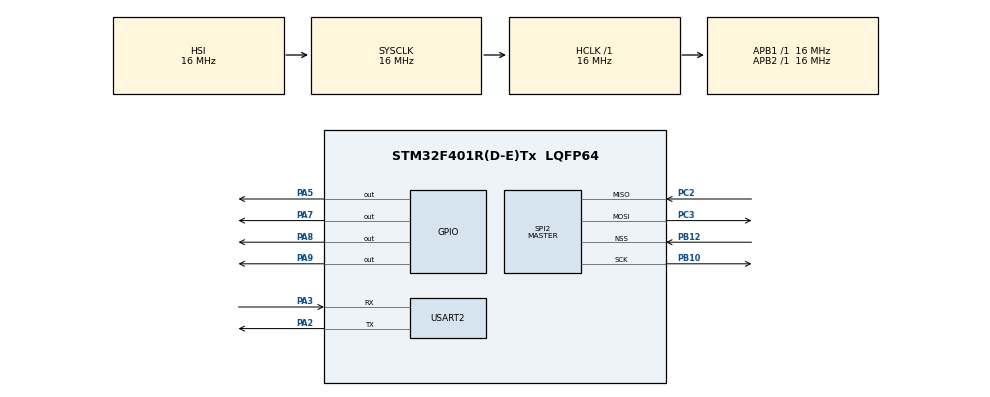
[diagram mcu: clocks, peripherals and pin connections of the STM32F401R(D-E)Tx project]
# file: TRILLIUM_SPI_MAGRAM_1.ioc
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Mcu.Family=STM32F4
Mcu.Name=STM32F401R(D-E)Tx
Mcu.Package=LQFP64
NVIC.PriorityGroup=NVIC_PRIORITYGROUP_4
PA2.Mode=Asynchronous
PA2.Signal=USART2_TX
PA3.Mode=Asynchronous
PA3.Signal=USART2_RX
PA5.Signal=GPIO_Output
PA7.Signal=GPIO_Output
PA8.Signal=GPIO_Output
PA9.Signal=GPIO_Output
PB10.Mode=Full_Duplex_Master
PB10.Signal=SPI2_SCK
PB12.Mode=NSS_Signal_Hard_Input
PB12.Signal=SPI2_NSS
PC2.Mode=Full_Duplex_Master
PC2.Signal=SPI2_MISO
PC3.Mode=Full_Duplex_Master
PC3.Signal=SPI2_MOSI
ProjectManager.HeapSize=0x200
ProjectManager.StackSize=0x400
ProjectManager.TargetToolchain=SW4STM32
RCC.AHBFreq_Value=16000000
RCC.APB1Freq_Value=16000000
RCC.APB2Freq_Value=16000000
RCC.CortexFreq_Value=16000000
RCC.HSE_VALUE=25000000
RCC.HSI_VALUE=16000000
RCC.LSE_VALUE=32768
RCC.SYSCLKFreq_VALUE=16000000
RCC.VCOOutputFreq_Value=192000000
SPI2.Direction=SPI_DIRECTION_2LINES
SPI2.Mode=SPI_MODE_MASTER
SPI2.VirtualNSS=VM_NSSHARD
SPI2.VirtualType=VM_MASTER
USART2.VirtualMode=VM_ASYNC
board=custom

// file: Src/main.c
/**
  ******************************************************************************
  * @file           : main.c
  * @brief          : Main program body
  ******************************************************************************
  ** This notice applies to any and all portions of this file
  * that are not between comment pairs USER CODE BEGIN and
  * USER CODE END. Other portions of this file, whether
  * inserted by the user or by software development tools
  * are owned by their respective copyright owners.
  *
  * COPYRIGHT(c) 2019 STMicroelectronics
  *
  * Redistribution and use in source and binary forms, with or without modification,
  * are permitted provided that the following conditions are met:
  *   1. Redistributions of source code must retain the above copyright notice,
  *      this list of conditions and the following disclaimer.
  *   2. Redistributions in binary form must reproduce the above copyright notice,
  *      this list of conditions and the following disclaimer in the documentation
  *      and/or other materials provided with the distribution.
  *   3. Neither the name of STMicroelectronics nor the names of its contributors
  *      may be used to endorse or promote products derived from this software
  *      without specific prior written permission.
  *
  * THIS SOFTWARE IS PROVIDED BY THE COPYRIGHT HOLDERS AND CONTRIBUTORS "AS IS"
  * AND ANY EXPRESS OR IMPLIED WARRANTIES, INCLUDING, BUT NOT LIMITED TO, THE
  * IMPLIED WARRANTIES OF MERCHANTABILITY AND FITNESS FOR A PARTICULAR PURPOSE ARE
  * DISCLAIMED. IN NO EVENT SHALL THE COPYRIGHT HOLDER OR CONTRIBUTORS BE LIABLE
  * FOR ANY DIRECT, INDIRECT, INCIDENTAL, SPECIAL, EXEMPLARY, OR CONSEQUENTIAL
  * DAMAGES (INCLUDING, BUT NOT LIMITED TO, PROCUREMENT OF SUBSTITUTE GOODS OR
  * SERVICES; LOSS OF USE, DATA, OR PROFITS; OR BUSINESS INTERRUPTION) HOWEVER
  * CAUSED AND ON ANY THEORY OF LIABILITY, WHETHER IN CONTRACT, STRICT LIABILITY,
  * OR TORT (INCLUDING NEGLIGENCE OR OTHERWISE) ARISING IN ANY WAY OUT OF THE USE
  * OF THIS SOFTWARE, EVEN IF ADVISED OF THE POSSIBILITY OF SUCH DAMAGE.
  *
  ******************************************************************************
  */
#include "main.h"
#include "stm32f4xx_hal.h"
#include "TRILLIUM_SPI.h"
#include "MRAM.h"

SPI_HandleTypeDef hspi2;

UART_HandleTypeDef huart2;

/* USER CODE BEGIN PV */
#define GPIO_MODE             0x00000003U
/* Private variables ---------------------------------------------------------*/

/* USER CODE END PV */

void SystemClock_Config(void);
static void MX_GPIO_Init(void);
static void MX_SPI2_Init(void);
static void MX_USART2_UART_Init(void);

/* USER CODE BEGIN PFP */
/* Private function prototypes -----------------------------------------------*/
void print_string(char msg[], int size);
/* USER CODE END PFP */

int main(void)
{

  /* MCU Configuration----------------------------------------------------------*/

  /* Reset of all peripherals, Initializes the Flash interface and the Systick. */
  HAL_Init();

  /* Configure the system clock */
  SystemClock_Config();

  /* USER CODE BEGIN SysInit */
  /* Initialize all configured peripherals */
  MX_GPIO_Init();
  MX_SPI2_Init();
  MX_USART2_UART_Init();
  /* USER CODE BEGIN 2 */
 // uint8_t	mram_status_read, mram_status_write;

  //uint8_t   data_write[] = "Test Data for Memory";
  //uint8_t   data_read[21];
  //uint32_t  address;

  // Initialize pins
 // init_mem();
  print_string("MRAM Initialized!\n", strlen("MRAM Initialized!\n"));

//  // Enable writing to status register
//  write_enable(1);
//
//  // Write to status register
//  mram_status_write = 0b01110011;
//  write_status(&mram_status_write);
//
//  // Check if write was executed properly
//  read_status(&mram_status_read);
//  if (mram_status_read == mram_status_write)
//	  print_string("Successful write to status register!\n\n", strlen("Successful write to status register!\n"));
//  else
//	  print_string("Failed write to status register\n", strlen("Failed write to status register\n"));
//
//  // Write to memory
//  address = 0x123456;
//  write_mem(address, 20, data_write);
//
//  // Read from memory
//  read_mem(address, 20, data_read);
//  int err = 0;
//  for (int i = 0; i < 20; i++) {
//	  if (data_read[i] != data_write[i])
//		  err = 1;
//  }
//  if (!err)
//	  print_string("Successful write to memory!\n", strlen("Successful write to memory!\n"));
//  else
//	  print_string("Failed write to memory!\n", strlen("Failed write to memory!\n"));
  /* USER CODE END SysInit */

  /* Infinite loop */
  char c = 'q';
  uint32_t ad = 0x123456;

  while (1)
  {
	  print_string("Waiting for pin to go low\n", strlen("Waiting for pin to go low\n"));

	  // Wait for pin to go low so this MCU is slave mode
	  while(HAL_GPIO_ReadPin(GPIOB, GPIO_PIN_12));

	  print_string("Waiting for pin to go high\n", strlen("Waiting for pin to go high\n"));

	  // Wait for pin to go high, means other MCU is done communicating
	  while(!HAL_GPIO_ReadPin(GPIOB, GPIO_PIN_12));

	  print_string("Switch IO 1\n", strlen("Switch IO 1\n"));
	  Switch_IO(1);
	  HAL_Delay(500);

	  print_string("Set slaves\n", strlen("Set slaves\n"));
	  Set_Slaves();
	  HAL_Delay(500);

	  print_string("Clear master reg\n", strlen("Clear master reg\n"));
	  Clear_Master_Register();

	  print_string("Read mem\n", strlen("Read mem\n"));
	  read_mem(ad, 1, (uint8_t *)&c);

	  print_string((uint8_t *)&c,1);
	  print_string("\n",1);

	 // Set_Masters();
	  print_string("Switch IO 0\n", strlen("Switch IO 0\n"));
	  Switch_IO(0);

  }

}

void print_string(char msg[], int size) {
	HAL_UART_Transmit(&huart2, (uint8_t *)msg, size, 0xFF);
}

void SystemClock_Config(void)
{

  RCC_OscInitTypeDef RCC_OscInitStruct;
  RCC_ClkInitTypeDef RCC_ClkInitStruct;

    /**Configure the main internal regulator output voltage
    */
  __HAL_RCC_PWR_CLK_ENABLE();

  __HAL_PWR_VOLTAGESCALING_CONFIG(PWR_REGULATOR_VOLTAGE_SCALE2);

    /**Initializes the CPU, AHB and APB busses clocks
    */
  RCC_OscInitStruct.OscillatorType = RCC_OSCILLATORTYPE_HSI;
  RCC_OscInitStruct.HSIState = RCC_HSI_ON;
  RCC_OscInitStruct.HSICalibrationValue = 16;
  RCC_OscInitStruct.PLL.PLLState = RCC_PLL_NONE;
  if (HAL_RCC_OscConfig(&RCC_OscInitStruct) != HAL_OK)
  {
    _Error_Handler(__FILE__, __LINE__);
  }

    /**Initializes the CPU, AHB and APB busses clocks
    */
  RCC_ClkInitStruct.ClockType = RCC_CLOCKTYPE_HCLK|RCC_CLOCKTYPE_SYSCLK
                              |RCC_CLOCKTYPE_PCLK1|RCC_CLOCKTYPE_PCLK2;
  RCC_ClkInitStruct.SYSCLKSource = RCC_SYSCLKSOURCE_HSI;
  RCC_ClkInitStruct.AHBCLKDivider = RCC_SYSCLK_DIV1;
  RCC_ClkInitStruct.APB1CLKDivider = RCC_HCLK_DIV1;
  RCC_ClkInitStruct.APB2CLKDivider = RCC_HCLK_DIV1;

  if (HAL_RCC_ClockConfig(&RCC_ClkInitStruct, FLASH_LATENCY_0) != HAL_OK)
  {
    _Error_Handler(__FILE__, __LINE__);
  }

    /**Configure the Systick interrupt time
    */
  HAL_SYSTICK_Config(HAL_RCC_GetHCLKFreq()/1000);

    /**Configure the Systick
    */
  HAL_SYSTICK_CLKSourceConfig(SYSTICK_CLKSOURCE_HCLK);

  /* SysTick_IRQn interrupt configuration */
  HAL_NVIC_SetPriority(SysTick_IRQn, 0, 0);
}

/* SPI2 init function */
static void MX_SPI2_Init(void)
{

  /* SPI2 parameter configuration*/
  hspi2.Instance = SPI2;
  hspi2.Init.Mode = SPI_MODE_MASTER;
  hspi2.Init.Direction = SPI_DIRECTION_2LINES;
  hspi2.Init.DataSize = SPI_DATASIZE_8BIT;
  hspi2.Init.CLKPolarity = SPI_POLARITY_LOW;
  hspi2.Init.CLKPhase = SPI_PHASE_1EDGE;
  hspi2.Init.NSS = SPI_NSS_HARD_INPUT;
  hspi2.Init.BaudRatePrescaler = SPI_BAUDRATEPRESCALER_2;
  hspi2.Init.FirstBit = SPI_FIRSTBIT_MSB;
  hspi2.Init.TIMode = SPI_TIMODE_DISABLE;
  hspi2.Init.CRCCalculation = SPI_CRCCALCULATION_DISABLE;
  hspi2.Init.CRCPolynomial = 10;
  if (HAL_SPI_Init(&hspi2) != HAL_OK)
  {
    _Error_Handler(__FILE__, __LINE__);
  }

}

/* USART2 init function */
static void MX_USART2_UART_Init(void)
{

  huart2.Instance = USART2;
  huart2.Init.BaudRate = 115200;
  huart2.Init.WordLength = UART_WORDLENGTH_8B;
  huart2.Init.StopBits = UART_STOPBITS_1;
  huart2.Init.Parity = UART_PARITY_NONE;
  huart2.Init.Mode = UART_MODE_TX_RX;
  huart2.Init.HwFlowCtl = UART_HWCONTROL_NONE;
  huart2.Init.OverSampling = UART_OVERSAMPLING_16;
  if (HAL_UART_Init(&huart2) != HAL_OK)
  {
    _Error_Handler(__FILE__, __LINE__);
  }

}

/** Configure pins as
        * Analog
        * Input
        * Output
        * EVENT_OUT
        * EXTI
*/
static void MX_GPIO_Init(void)
{

  GPIO_InitTypeDef GPIO_InitStruct;

  /* GPIO Ports Clock Enable */
  __HAL_RCC_GPIOC_CLK_ENABLE();
  __HAL_RCC_GPIOA_CLK_ENABLE();
  __HAL_RCC_GPIOB_CLK_ENABLE();

  /*Configure GPIO pin Output Level */
  HAL_GPIO_WritePin(GPIOA, GPIO_PIN_5, GPIO_PIN_RESET);

  /*Configure GPIO pins : PA5 */
  GPIO_InitStruct.Pin = GPIO_PIN_5;
  GPIO_InitStruct.Mode = GPIO_MODE_OUTPUT_PP;
  GPIO_InitStruct.Pull = GPIO_NOPULL;
  GPIO_InitStruct.Speed = GPIO_SPEED_FREQ_LOW;
  HAL_GPIO_Init(GPIOA, &GPIO_InitStruct);

  /*Configure GPIO pins : PA7 PA8 PA9 */
  GPIO_InitStruct.Pin = GPIO_PIN_7|GPIO_PIN_8|GPIO_PIN_9;
  GPIO_InitStruct.Mode = GPIO_MODE_INPUT;
  GPIO_InitStruct.Pull = GPIO_NOPULL;
  GPIO_InitStruct.Speed = GPIO_SPEED_FREQ_LOW;
  HAL_GPIO_Init(GPIOA, &GPIO_InitStruct);

}

void _Error_Handler(char *file, int line)
{
  while(1)
  {
  }
}

/************************ (C) COPYRIGHT STMicroelectronics *****END OF FILE****/
